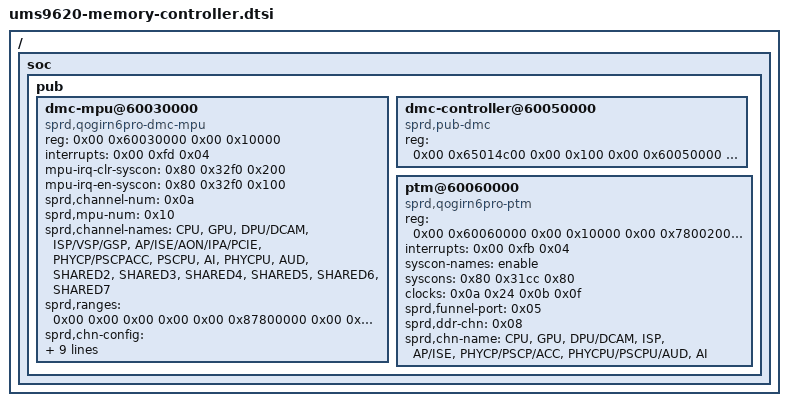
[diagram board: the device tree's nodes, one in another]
// W202DS Server hardware layout; split from the validated imported tree.
/ {
	soc {
		pub {
			dmc-mpu@60030000 {
				compatible = "sprd,qogirn6pro-dmc-mpu", "sprd,qogirl6-dmc-mpu";
				reg = <0x00 0x60030000 0x00 0x10000>;
				interrupts = <0x00 0xfd 0x04>;
				mpu-irq-clr-syscon = <0x80 0x32f0 0x200>;
				mpu-irq-en-syscon = <0x80 0x32f0 0x100>;
				sprd,channel-num = <0x0a>;
				sprd,mpu-num = <0x10>;
				sprd,channel-names = "CPU", "GPU", "DPU/DCAM", "ISP/VSP/GSP", "AP/ISE/AON/IPA/PCIE", "PHYCP/PSCPACC", "PSCPU", "AI", "PHYCPU", "AUD", "SHARED2", "SHARED3", "SHARED4", "SHARED5", "SHARED6", "SHARED7";
				sprd,ranges = <0x00 0x00 0x00 0x00 0x00 0x87800000 0x00 0xa5000000 0x00 0x87800000 0x00 0xa5000000 0x00 0x87800000 0x00 0xa5000000 0x00 0x91800000 0x00 0xa5000000 0x00 0x87800000 0x00 0xa5000000 0x00 0x87800000 0x00 0xa5000000 0x00 0x87800000 0x00 0xa5000000 0x00 0x87800000 0x00 0xa5000000 0x00 0x87800000 0x00 0xa5000000 0x00 0x00 0x00 0x00 0x00 0x00 0x00 0x00 0x00 0x00 0x00 0x00 0x00 0x00 0x00 0x00 0x00 0x00 0x00 0x00 0x00 0x00 0x00 0x00>;
				sprd,chn-config = <0x00 0x01 0x01 0x01 0x01 0x01 0x01 0x01 0x01 0x01 0x01 0x01 0x01 0x01 0x01 0x01 0x00 0x01 0x01 0x00 0x01 0x01 0x01 0x01 0x01 0x00 0x01 0x01 0x01 0x01 0x00 0x01 0x01 0x00 0x01 0x01 0x00 0x01 0x01 0x00 0x01 0x01 0x00 0x01 0x01 0x00 0x01 0x01>;
				sprd,id-config = <0x00 0x00 0xffff 0x00 0x00 0xffff 0x00 0x00 0xffff 0x00 0x00 0xffff 0x00 0x00 0xffff 0x00 0x00 0xffff 0x00 0xd2 0x00 0x00 0x00 0xffff 0x00 0xda 0x00 0x00 0x9f 0x00 0x00 0x00 0xffff 0x00 0x00 0xffff 0x00 0x00 0xffff 0x00 0x00 0xffff 0x00 0x00 0xffff 0x00 0x00 0xffff>;
				sprd,port-map = <0x00 0x01 0x02 0x03 0x04 0x05 0x06 0x07 0x06 0x06 0x00 0x00 0x00 0x00 0x00 0x00>;
				sprd,ddrc-remap = <0x60000014 0x0d 0x6000009c 0xdeadbeef>;
				sprd,ddr-offset = <0x80000000>;
				status = "okay";
				sprd,panic;
				phandle = <0x1ba>;
			};
			dmc-controller@60050000 {
				compatible = "sprd,pub-dmc";
				reg = <0x00 0x65014c00 0x00 0x100 0x00 0x60050000 0x00 0x8010 0x00 0x60000000 0x00 0x670>;
				phandle = <0x1bb>;
			};
			ptm@60060000 {
				compatible = "sprd,qogirn6pro-ptm";
				reg = <0x00 0x60060000 0x00 0x10000 0x00 0x78002000 0x00 0x1000 0x00 0x78003000 0x00 0x1000 0x00 0x78006000 0x00 0x1000>;
				interrupts = <0x00 0xfb 0x04>;
				syscon-names = "enable";
				syscons = <0x80 0x31cc 0x80>;
				clock-names = "clk_cs", "cs_src";
				clocks = <0x0a 0x24 0x0b 0x0f>;
				sprd,funnel-port = <0x05>;
				sprd,ddr-chn = <0x08>;
				sprd,chn-name = "CPU", "GPU", "DPU/DCAM", "ISP", "AP/ISE", "PHYCP/PSCP/ACC", "PHYCPU/PSCPU/AUD", "AI";
				phandle = <0x1bc>;
			};
		};
	};
	__symbols__ {
		dmc_mpu = "/soc/pub/dmc-mpu@60030000";
		dmc_controller = "/soc/pub/dmc-controller@60050000";
		ptm_trace = "/soc/pub/ptm@60060000";
	};
};
